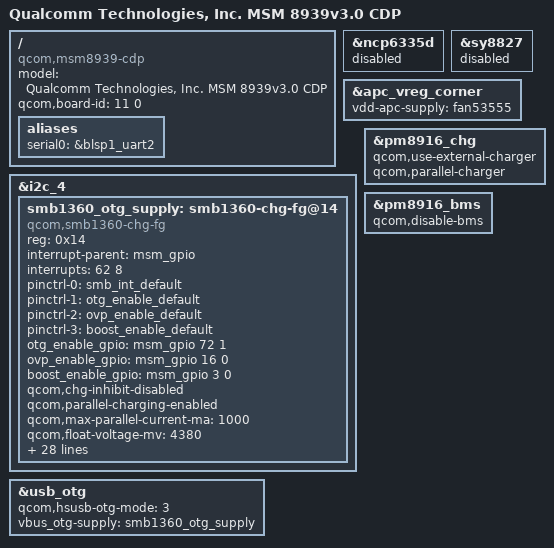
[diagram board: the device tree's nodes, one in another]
/*
 * Copyright (c) 2015, The Linux Foundation. All rights reserved.
 *
 * This program is free software; you can redistribute it and/or modify
 * it under the terms of the GNU General Public License version 2 and
 * only version 2 as published by the Free Software Foundation.
 *
 * This program is distributed in the hope that it will be useful,
 * but WITHOUT ANY WARRANTY; without even the implied warranty of
 * MERCHANTABILITY or FITNESS FOR A PARTICULAR PURPOSE.  See the
 * GNU General Public License for more details.
 */

/dts-v1/;

#include "zc550kl/zc550kl_msm8939-ER-v3.0.dtsi"
#include "zc550kl/zc550kl_msm8939-ER-cdp.dtsi"

/ {
	model = "Qualcomm Technologies, Inc. MSM 8939v3.0 CDP";
	compatible = "qcom,msm8939-cdp", "qcom,msm8939", "qcom,cdp";
	qcom,board-id = <11 0>;
	
	aliases {
		serial0 = &blsp1_uart2;
	};
};

&ncp6335d {
	status = "disabled";
};

&sy8827 {
	status = "disabled";
};

&apc_vreg_corner {
	vdd-apc-supply = <&fan53555>;
};

&i2c_4 {
	smb1360_otg_supply: smb1360-chg-fg@14 {
			compatible = "qcom,smb1360-chg-fg";
			reg = <0x14>;
			interrupt-parent = <&msm_gpio>;
			interrupts = <62 8>;
			pinctrl-names = "default","otg_enable_default","ovp_enable_default", "boost_enable_default";
			pinctrl-0 = <&smb_int_default>;
			pinctrl-1 = <&otg_enable_default>;
			pinctrl-2 = <&ovp_enable_default>;
			pinctrl-3 = <&boost_enable_default>;
			otg_enable_gpio = <&msm_gpio 72 1>;
			ovp_enable_gpio = <&msm_gpio 16 0>;
			boost_enable_gpio = <&msm_gpio 3 0>;
			qcom,chg-inhibit-disabled;
			qcom,parallel-charging-enabled;
			qcom,max-parallel-current-ma = <1000>;
			qcom,float-voltage-mv = <4380>;
			qcom,iterm-ma = <200>;
			qcom,fg-iterm-ma = <250>;
			qcom,recharge-thresh-mv = <100>;
			qcom,thermal-mitigation = <1500 1400 600 0>;
			qcom,min-icl-100ma;
			qcom,fg-auto-recharge-soc = <99>;
			qcom,smb1360-vadc = <&pm8916_vadc>;
			qcom,otg-batt-curr-limit = <950>;
			qcom,config-hard-thresholds;
			qcom,hot-bat-decidegc = <600>;
			qcom,cold-bat-decidegc = <0>;
			// asus bsp frank add soft jeita for cool and warm +++
			qcom,soft-jeita-supported;
			qcom,warm-bat-decidegc = <500>;
			qcom,cool-bat-decidegc = <100>;
			qcom,warm-bat-mv = <4100>;
			qcom,cool-bat-mv = <4380>;
			qcom,warm-bat-ma = <1500>;
			qcom,cool-bat-ma = <450>;
			// asus bsp frank add soft jeita for cool and warm ---
			qcom,shdn-after-pwroff;
			regulator-name = "smb1360_otg_vreg";
			qcom,fg-batt-capacity-mah = <4850>;
			qcom,fg-cc-soc-coeff = <0x7AC2>;
			qcom,fg-cc-to-cv-mv = <4360>;
			qcom,thermistor-c1-coeff = <0x86DA>;
			qcom,otp-rslow-cfg;
			otp_jeita_hard_config;
			qcom,rsense-10mhom;
			qcom,charging-timeout = <0>;
	};
};

&pm8916_chg {
	status = "ok";
	qcom,use-external-charger;
	qcom,parallel-charger;
};

&pm8916_bms {
	status = "ok";
	qcom,disable-bms;
};

&usb_otg {
	qcom,hsusb-otg-mode = <3>;
	vbus_otg-supply = <&smb1360_otg_supply>;
};
